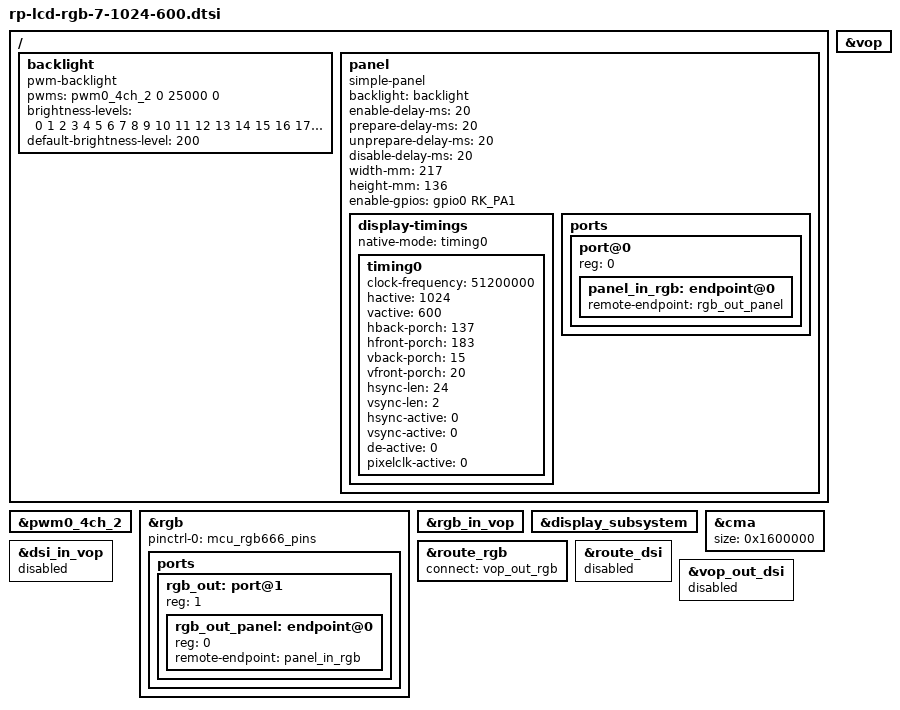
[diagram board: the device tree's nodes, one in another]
/{
    backlight: backlight {
        compatible = "pwm-backlight";
        pwms = <&pwm0_4ch_2 0 25000 0>;
        brightness-levels = <
            0   1   2   3   4   5   6   7
            8   9  10  11  12  13  14  15
            16  17  18  19  20  21  22  23
            24  25  26  27  28  29  30  31
            32  33  34  35  36  37  38  39
            40  41  42  43  44  45  46  47
            48  49  50  51  52  53  54  55
            56  57  58  59  60  61  62  63
            64  65  66  67  68  69  70  71
            72  73  74  75  76  77  78  79
            80  81  82  83  84  85  86  87
            88  89  90  91  92  93  94  95
            96  97  98  99 100 101 102 103
            104 105 106 107 108 109 110 111
            112 113 114 115 116 117 118 119
            120 121 122 123 124 125 126 127
            128 129 130 131 132 133 134 135
            136 137 138 139 140 141 142 143
            144 145 146 147 148 149 150 151
            152 153 154 155 156 157 158 159
            160 161 162 163 164 165 166 167
            168 169 170 171 172 173 174 175
            176 177 178 179 180 181 182 183
            184 185 186 187 188 189 190 191
            192 193 194 195 196 197 198 199
            200 201 202 203 204 205 206 207
            208 209 210 211 212 213 214 215
            216 217 218 219 220 221 222 223
            224 225 226 227 228 229 230 231
            232 233 234 235 236 237 238 239
            240 241 242 243 244 245 246 247
            248 249 250 251 252 253 254 255>;
        default-brightness-level = <200>;
    };

    panel {
        status = "okay";
        compatible = "simple-panel";
        backlight = <&backlight>;
        
        enable-delay-ms = <20>;
        prepare-delay-ms = <20>;
        unprepare-delay-ms = <20>;
        disable-delay-ms = <20>;
        //bus-format = <MEDIA_BUS_BGR888_1X24>;
        //pinctrl-0 = <&rgb888_pins>;
        
        width-mm = <217>;
        height-mm = <136>;       
        /**
        * power-supply = <>;
        * reset-gpios = <>;
        *
        * lcd reset pin and power supply
        * please refer to ***-lcd-gpio.dtsi
        * that included in main dts.
        */
        //power-supply = <&vcc18_lcd_n>;
        enable-gpios = <&gpio0 RK_PA1 GPIO_ACTIVE_HIGH>;
        //  reset-gpios = <&gpio0 RK_PC2 GPIO_ACTIVE_LOW>;
        
        display-timings {
            native-mode = <&timing0>;
            timing0: timing0 {
                clock-frequency = <51200000>;
                hactive = <1024>;
                vactive = <600>;
                hback-porch = <137>;
                hfront-porch = <183>;
                vback-porch = <15>;
                vfront-porch = <20>;
                hsync-len = <24>;
                vsync-len = <2>;
                hsync-active = <0>;
                vsync-active = <0>;
                de-active = <0>;
                pixelclk-active = <0>;
            };
        };
        
        ports {
            #address-cells = <1>;
            #size-cells = <0>;
            port@0 {
                reg = <0>;
                panel_in_rgb: endpoint@0 {
                    remote-endpoint = <&rgb_out_panel>;
                };
            };
        };
    };

};	
		
&pwm0_4ch_2 {
    status = "okay";
};

&rgb {
    status = "okay";
    pinctrl-names = "default";
    pinctrl-0 = <&mcu_rgb666_pins>;
    ports {
        rgb_out: port@1 {
            reg = <1>;
            #address-cells = <1>;
            #size-cells = <0>;
            rgb_out_panel: endpoint@0 {
                reg = <0>;
                remote-endpoint = <&panel_in_rgb>;
            };
        };
    };
};

&rgb_in_vop {
	status = "okay";
};

&display_subsystem {
	status = "okay";
};

&cma {          
    size = <0x1600000>;
};

&vop {
	status = "okay";
};

&route_rgb {
	connect = <&vop_out_rgb>;
	status = "okay";
};

&dsi_in_vop {
        status = "disabled";
};

&route_dsi {
        status = "disabled";
};

&vop_out_dsi {
    status = "disabled";
};











